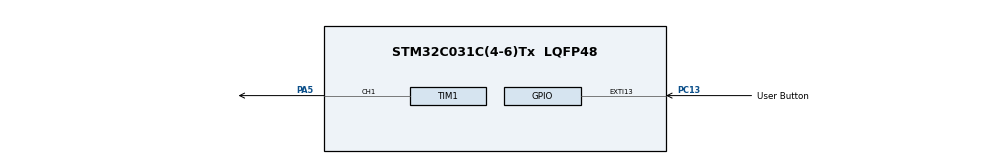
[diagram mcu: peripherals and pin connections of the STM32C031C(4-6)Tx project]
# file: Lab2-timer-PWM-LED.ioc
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Mcu.Family=STM32C0
Mcu.Name=STM32C031C(4-6)Tx
Mcu.Package=LQFP48
NVIC.EXTI4_15_IRQn=true\:0\:0\:false\:false\:true\:true\:true\:true
PA13.Signal=DEBUG_SWDIO
PA14-BOOT0.Signal=DEBUG_SWCLK
PA2.Signal=USART2_TX
PA3.Signal=USART2_RX
PA5.Signal=S_TIM1_CH1
PB8.Signal=I2C1_SCL
PB9.Signal=I2C1_SDA
PC13.GPIO_Label=User Button
PC13.Signal=GPXTI13
PC14-OSCX_IN\ (PC14).Signal=RCC_OSCX_IN
PC15-OSCX_OUT\ (PC15).Signal=RCC_OSCX_OUT
PF0-OSC_IN\ (PF0).Signal=RCC_OSC_IN
PF1-OSC_OUT\ (PF1).Signal=RCC_OSC_OUT
ProjectManager.HeapSize=0x200
ProjectManager.StackSize=0x400
ProjectManager.TargetToolchain=STM32CubeIDE
RCC.ADCFreq_Value=48000000
RCC.AHBFreq_Value=48000000
RCC.APB1CLKDivider=RCC_APB1_DIV16
RCC.CortexFreq_Value=48000000
RCC.EXTERNAL_CLOCK_VALUE=12288000
RCC.HCLKFreq_Value=48000000
RCC.HSE_VALUE=48000000
RCC.HSISYSCLKDivider=RCC_HSI_DIV1
RCC.HSI_VALUE=48000000
RCC.LSE_VALUE=32768
RCC.SYSCLKFreq_VALUE=48000000
SH.S_TIM1_CH1.0=TIM1_CH1,PWM Generation1 CH1
TIM1.Channel-PWM\ Generation1\ CH1=TIM_CHANNEL_1
TIM1.Period=46875
TIM1.Prescaler=128
TIM1.Pulse-PWM\ Generation1\ CH1=23474
VP_TIM1_VS_ClockSourceINT.Mode=Internal
board=NUCLEO-C031C6

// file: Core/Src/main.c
/* USER CODE BEGIN Header */
/**
  ******************************************************************************
  * @file           : main.c
  * @brief          : Main program body
  ******************************************************************************
  * @attention
  *
  * Copyright (c) 2023 STMicroelectronics.
  * All rights reserved.
  *
  * This software is licensed under terms that can be found in the LICENSE file
  * in the root directory of this software component.
  * If no LICENSE file comes with this software, it is provided AS-IS.
  *
  ******************************************************************************
  */
/* USER CODE END Header */
#include "main.h"

TIM_HandleTypeDef htim1;

/* USER CODE BEGIN PV */
uint32_t uwNewPulse = 23447;

/* USER CODE END PV */

void SystemClock_Config(void);
static void MX_GPIO_Init(void);
static void MX_TIM1_Init(void);

int main(void)
{
  /* USER CODE BEGIN 1 */
uint32_t uwTimerPulse = 0;

  /* USER CODE END 1 */

  /* MCU Configuration--------------------------------------------------------*/

  /* Reset of all peripherals, Initializes the Flash interface and the Systick. */
  HAL_Init();

  /* Configure the system clock */
  SystemClock_Config();

  /* Initialize all configured peripherals */
  MX_GPIO_Init();
  MX_TIM1_Init();
  /* USER CODE BEGIN 2 */

  HAL_TIM_PWM_Start(&htim1, TIM_CHANNEL_1);

  /* USER CODE END 2 */

  /* Infinite loop */
  /* USER CODE BEGIN WHILE */
  while (1)
  {
	  if (uwTimerPulse != uwNewPulse)
	  {
		  uwTimerPulse = uwNewPulse;
		  // should set the pulse here:
	  }

    /* USER CODE END WHILE */

  }
}

void SystemClock_Config(void)
{
  RCC_OscInitTypeDef RCC_OscInitStruct = {0};
  RCC_ClkInitTypeDef RCC_ClkInitStruct = {0};

  /** Initializes the RCC Oscillators according to the specified parameters
  * in the RCC_OscInitTypeDef structure.
  */
  RCC_OscInitStruct.OscillatorType = RCC_OSCILLATORTYPE_HSI;
  RCC_OscInitStruct.HSIState = RCC_HSI_ON;
  RCC_OscInitStruct.HSIDiv = RCC_HSI_DIV1;
  RCC_OscInitStruct.HSICalibrationValue = RCC_HSICALIBRATION_DEFAULT;
  if (HAL_RCC_OscConfig(&RCC_OscInitStruct) != HAL_OK)
  {
    Error_Handler();
  }

  /** Initializes the CPU, AHB and APB buses clocks
  */
  RCC_ClkInitStruct.ClockType = RCC_CLOCKTYPE_HCLK|RCC_CLOCKTYPE_SYSCLK
                              |RCC_CLOCKTYPE_PCLK1;
  RCC_ClkInitStruct.SYSCLKSource = RCC_SYSCLKSOURCE_HSI;
  RCC_ClkInitStruct.SYSCLKDivider = RCC_SYSCLK_DIV1;
  RCC_ClkInitStruct.AHBCLKDivider = RCC_HCLK_DIV1;
  RCC_ClkInitStruct.APB1CLKDivider = RCC_APB1_DIV16;

  if (HAL_RCC_ClockConfig(&RCC_ClkInitStruct, FLASH_LATENCY_1) != HAL_OK)
  {
    Error_Handler();
  }
}

static void MX_TIM1_Init(void)
{

  TIM_ClockConfigTypeDef sClockSourceConfig = {0};
  TIM_MasterConfigTypeDef sMasterConfig = {0};
  TIM_OC_InitTypeDef sConfigOC = {0};
  TIM_BreakDeadTimeConfigTypeDef sBreakDeadTimeConfig = {0};

  htim1.Instance = TIM1;
  htim1.Init.Prescaler = 128;
  htim1.Init.CounterMode = TIM_COUNTERMODE_UP;
  htim1.Init.Period = 46875;
  htim1.Init.ClockDivision = TIM_CLOCKDIVISION_DIV1;
  htim1.Init.RepetitionCounter = 0;
  htim1.Init.AutoReloadPreload = TIM_AUTORELOAD_PRELOAD_DISABLE;
  if (HAL_TIM_Base_Init(&htim1) != HAL_OK)
  {
    Error_Handler();
  }
  sClockSourceConfig.ClockSource = TIM_CLOCKSOURCE_INTERNAL;
  if (HAL_TIM_ConfigClockSource(&htim1, &sClockSourceConfig) != HAL_OK)
  {
    Error_Handler();
  }
  if (HAL_TIM_PWM_Init(&htim1) != HAL_OK)
  {
    Error_Handler();
  }
  sMasterConfig.MasterOutputTrigger = TIM_TRGO_RESET;
  sMasterConfig.MasterOutputTrigger2 = TIM_TRGO2_RESET;
  sMasterConfig.MasterSlaveMode = TIM_MASTERSLAVEMODE_DISABLE;
  if (HAL_TIMEx_MasterConfigSynchronization(&htim1, &sMasterConfig) != HAL_OK)
  {
    Error_Handler();
  }
  sConfigOC.OCMode = TIM_OCMODE_PWM1;
  sConfigOC.Pulse = 23474;
  sConfigOC.OCPolarity = TIM_OCPOLARITY_HIGH;
  sConfigOC.OCNPolarity = TIM_OCNPOLARITY_HIGH;
  sConfigOC.OCFastMode = TIM_OCFAST_DISABLE;
  sConfigOC.OCIdleState = TIM_OCIDLESTATE_RESET;
  sConfigOC.OCNIdleState = TIM_OCNIDLESTATE_RESET;
  if (HAL_TIM_PWM_ConfigChannel(&htim1, &sConfigOC, TIM_CHANNEL_1) != HAL_OK)
  {
    Error_Handler();
  }
  sBreakDeadTimeConfig.OffStateRunMode = TIM_OSSR_DISABLE;
  sBreakDeadTimeConfig.OffStateIDLEMode = TIM_OSSI_DISABLE;
  sBreakDeadTimeConfig.LockLevel = TIM_LOCKLEVEL_OFF;
  sBreakDeadTimeConfig.DeadTime = 0;
  sBreakDeadTimeConfig.BreakState = TIM_BREAK_DISABLE;
  sBreakDeadTimeConfig.BreakPolarity = TIM_BREAKPOLARITY_HIGH;
  sBreakDeadTimeConfig.BreakFilter = 0;
  sBreakDeadTimeConfig.BreakAFMode = TIM_BREAK_AFMODE_INPUT;
  sBreakDeadTimeConfig.Break2State = TIM_BREAK2_DISABLE;
  sBreakDeadTimeConfig.Break2Polarity = TIM_BREAK2POLARITY_HIGH;
  sBreakDeadTimeConfig.Break2Filter = 0;
  sBreakDeadTimeConfig.Break2AFMode = TIM_BREAK_AFMODE_INPUT;
  sBreakDeadTimeConfig.AutomaticOutput = TIM_AUTOMATICOUTPUT_DISABLE;
  if (HAL_TIMEx_ConfigBreakDeadTime(&htim1, &sBreakDeadTimeConfig) != HAL_OK)
  {
    Error_Handler();
  }
  HAL_TIM_MspPostInit(&htim1);

}

static void MX_GPIO_Init(void)
{
  GPIO_InitTypeDef GPIO_InitStruct = {0};

  /* GPIO Ports Clock Enable */
  __HAL_RCC_GPIOC_CLK_ENABLE();
  __HAL_RCC_GPIOF_CLK_ENABLE();
  __HAL_RCC_GPIOA_CLK_ENABLE();
  __HAL_RCC_GPIOB_CLK_ENABLE();

  /*Configure GPIO pin : User_Button_Pin */
  GPIO_InitStruct.Pin = User_Button_Pin;
  GPIO_InitStruct.Mode = GPIO_MODE_IT_RISING;
  GPIO_InitStruct.Pull = GPIO_NOPULL;
  HAL_GPIO_Init(User_Button_GPIO_Port, &GPIO_InitStruct);

  /*Configure GPIO pins : PA2 PA3 */
  GPIO_InitStruct.Pin = GPIO_PIN_2|GPIO_PIN_3;
  GPIO_InitStruct.Mode = GPIO_MODE_AF_PP;
  GPIO_InitStruct.Pull = GPIO_NOPULL;
  GPIO_InitStruct.Speed = GPIO_SPEED_FREQ_LOW;
  GPIO_InitStruct.Alternate = GPIO_AF1_USART2;
  HAL_GPIO_Init(GPIOA, &GPIO_InitStruct);

  /*Configure GPIO pins : PB8 PB9 */
  GPIO_InitStruct.Pin = GPIO_PIN_8|GPIO_PIN_9;
  GPIO_InitStruct.Mode = GPIO_MODE_AF_OD;
  GPIO_InitStruct.Pull = GPIO_NOPULL;
  GPIO_InitStruct.Speed = GPIO_SPEED_FREQ_LOW;
  GPIO_InitStruct.Alternate = GPIO_AF6_I2C1;
  HAL_GPIO_Init(GPIOB, &GPIO_InitStruct);

  /* EXTI interrupt init*/
  HAL_NVIC_SetPriority(EXTI4_15_IRQn, 0, 0);
  HAL_NVIC_EnableIRQ(EXTI4_15_IRQn);

}

void Error_Handler(void)
{
  __disable_irq();
  while (1)
  {
  }
}
